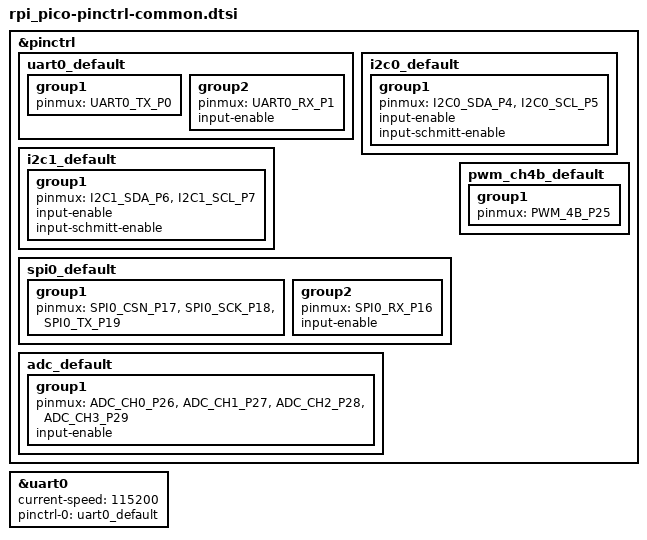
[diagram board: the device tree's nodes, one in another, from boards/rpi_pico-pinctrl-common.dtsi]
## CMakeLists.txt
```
# Minimum Cmake version required to build this project
cmake_minimum_required(VERSION 3.20)

# Locate the Zephyr RTOS source
find_package(Zephyr REQUIRED HINTS $ENV{ZEPHYR_BASE})

# Name the project
project(MeshFlipper)

list(APPEND CMAKE_MODULE_PATH ${ZEPHYR_BASE}/modules/nanopb)
include(nanopb)

# Make protobufs/ available as an import root so "meshtastic/foo.proto" resolves.
list(APPEND NANOPB_IMPORT_DIRS ${CMAKE_CURRENT_SOURCE_DIR}/protobufs)

# Compile mesh.proto and all its transitive dependencies.
zephyr_nanopb_sources(app
    protobufs/meshtastic/mesh.proto
    protobufs/meshtastic/channel.proto
    protobufs/meshtastic/config.proto
    protobufs/meshtastic/device_ui.proto
    protobufs/meshtastic/module_config.proto
    protobufs/meshtastic/atak.proto
    protobufs/meshtastic/portnums.proto
    protobufs/meshtastic/telemetry.proto
    protobufs/meshtastic/xmodem.proto
)

# Generated .pb.h files land in build/protobufs/meshtastic/ but are included as
# "meshtastic/X.pb.h", so build/protobufs/ must be on the include path.
target_include_directories(app PUBLIC ${CMAKE_CURRENT_BINARY_DIR}/protobufs)

# Locate the source code for the application
target_sources(
    app
    PRIVATE
    src/main.c
    src/models/ring_buffer.c
    src/models/mesh_message.c
    src/models/mesh_node.c
    src/hardware/uart_hal.c
    src/comms/uart_comms.c
    src/comms/protobuf_handler.c
    src/tasks/message_processor.c
    src/hardware/button_hal.c
    src/hardware/button.c
    src/ui/ui_button_handler.c
    src/hardware/display_hal.c
    src/hardware/display_hal_weact.c
    src/middleware/display_driver.c
    src/ui/on_screen_keyb.c
    src/ui/display_ui_core.c
    src/ui/display_ui_actions.c
    src/ui/display_ui_keyboard.c
)

target_include_directories(
    app
    PRIVATE
    include
)
```

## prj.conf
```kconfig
CONFIG_SERIAL=y
CONFIG_UART_INTERRUPT_DRIVEN=y
CONFIG_NANOPB=y
CONFIG_SPI=y
CONFIG_GPIO=y
```

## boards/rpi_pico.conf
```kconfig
# Was being used for usb serial console, but using cp2102 usb to uart bridge instead, so disabling usb device stack for now
# CONFIG_USB_DEVICE_STACK=y
# CONFIG_USB_DEVICE_VID=0x2FE3
# CONFIG_USB_DEVICE_PID=0x0004
# CONFIG_USB_DEVICE_PRODUCT="USB CDC-ACM serial console"

CONFIG_SERIAL=y
CONFIG_UART_INTERRUPT_DRIVEN=y
CONFIG_SPI=y
CONFIG_NANOPB=y
CONFIG_HEAP_MEM_POOL_SIZE=4096
CONFIG_MAIN_STACK_SIZE=4096
```

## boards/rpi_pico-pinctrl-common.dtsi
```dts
/*
 * Copyright (c) 2021, Yonatan Schachter
 * SPDX-License-Identifier: Apache-2.0
 */


#include <../../include/zephyr/dt-bindings/pinctrl/rpi-pico-pinctrl-common.h>

/* The Pico and Pico 2 are pin compatible. */
&pinctrl {
	uart0_default: uart0_default {
		group1 {
			pinmux = <UART0_TX_P0>;
		};

		group2 {
			pinmux = <UART0_RX_P1>;
			input-enable;
		};
	};

	i2c0_default: i2c0_default {
		group1 {
			pinmux = <I2C0_SDA_P4>, <I2C0_SCL_P5>;
			input-enable;
			input-schmitt-enable;
		};
	};

	i2c1_default: i2c1_default {
		group1 {
			pinmux = <I2C1_SDA_P6>, <I2C1_SCL_P7>;
			input-enable;
			input-schmitt-enable;
		};
	};

	spi0_default: spi0_default {
		group1 {
			pinmux = <SPI0_CSN_P17>, <SPI0_SCK_P18>, <SPI0_TX_P19>;
		};

		group2 {
			pinmux = <SPI0_RX_P16>;
			input-enable;
		};
	};

	pwm_ch4b_default: pwm_ch4b_default {
		group1 {
			pinmux = <PWM_4B_P25>;
		};
	};

	adc_default: adc_default {
		group1 {
			pinmux = <ADC_CH0_P26>, <ADC_CH1_P27>, <ADC_CH2_P28>, <ADC_CH3_P29>;
			input-enable;
		};
	};
};

/* Add this below your existing &pinctrl block */
&uart0 {
    status = "okay";
    current-speed = <115200>;
    pinctrl-0 = <&uart0_default>;
    pinctrl-names = "default";
};
```

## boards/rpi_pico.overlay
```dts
/ {
	leds {
		compatible = "gpio-leds";
		led0: led_0 {
			gpios = <&gpio0 6 GPIO_ACTIVE_HIGH>;
				label = "LED 0";
		};
	};

	aliases {
		led0 = &led0;
	};
};

&pinctrl {
	uart0_default: uart0_default {
		group1 {
			pinmux = <UART0_TX_P0>;
		};

		group2 {
			pinmux = <UART0_RX_P1>;
			input-enable;
		};
	};

	spi0_default: spi0_default {
		group1 {
			pinmux = <SPI0_SCK_P18 SPI0_TX_P19>;
		};
	};
};

&uart0 {
    status = "okay";
    current-speed = <115200>;
    pinctrl-0 = <&uart0_default>;
    pinctrl-names = "default";
};

&spi0 {
	status = "okay";
	pinctrl-0 = <&spi0_default>;
	pinctrl-names = "default";
};
```

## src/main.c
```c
#include <stdio.h>
#include <zephyr/kernel.h>
#include <zephyr/drivers/uart.h>

#include "hardware/uart_hal.h"
#include "hardware/display_hal_weact.h"
#include "ui/on_screen_keyb.h"
#include "comms/uart_comms.h"
#include "models/ring_buffer.h"
#include "models/mesh_message.h"
#include "models/mesh_node.h"
#include "tasks/message_processor.h"
#include "comms/protobuf_handler.h"
#include "ui/display_ui.h"
#include "ui/ui_button_handler.h"



// Global instances
struct messageHistory g_message_history = { .count = 0 };
struct nodeHistory g_node_list = { .count = 0 };
ring_buffer_t g_msg_ring_buffer;

// Display and UI instances
static display_ui_t g_display_ui;
static ui_button_context_t g_button_ctx;
static on_screen_keyb_t g_on_screen_keyb;




static int setup_uart_hal(void) 
{
    const struct device *uart_dev = DEVICE_DT_GET(DT_NODELABEL(uart0));

    if (uart_hal_init(&g_uart_hal, uart_dev) != 0) {
        printk("UART HAL init failed\n");
        return -1;
    }

    if (uart_hal_configure_default(&g_uart_hal) != 0) {
        printk("UART configure failed\n");
        return -1;
    }

    uart_comms_init(&g_uart_comms, &g_uart_hal);

    // Set UART callback to HAL's ISR handler
    uart_irq_callback_user_data_set(uart_dev, uart_hal_isr_handler, &g_uart_hal);

    // Set the HAL callback to forward to uart_comms
    uart_hal_set_rx_callback(&g_uart_hal, uart_comms_process_byte, &g_uart_comms);
    
    uart_hal_irq_enable(&g_uart_hal);
    
    return 0;
}

static int setup_message_processor(void) 
{
    if (message_processor_init(&g_msg_ring_buffer, 
                               &g_message_history, 
                               &g_node_list) != 0) {
        printk("Message processor init failed\n");
        return -1;
    } 

    if (message_processor_start() != 0) {
        printk("Message processor start failed\n");
        return -1;
    }

    return 0;
}

static int setup_display(void)
{
    display_hal_config_t hal_config = weact_display_get_config();
    
    int ret = display_ui_init(&g_display_ui, &hal_config, &g_message_history, &g_node_list);
    if (ret < 0) {
        printk("Display UI init failed: %d\n", ret);
        return -1;
    }
    message_processor_set_display_ui(&g_display_ui);
    display_ui_show_boot(&g_display_ui);

    return 0;
}

static int setup_buttons(void)
{
    int ret = ui_button_handler_init(&g_button_ctx, &g_display_ui);
    if (ret < 0) {
        printk("Button handler init failed: %d\n", ret);
        return -1;
    }

    // Start button handler thread
    ret = ui_button_handler_start();
    if (ret < 0) {
        printk("Button handler start failed: %d\n", ret);
        return -1;
    }

    return 0;
}

static int setup_on_screen_keyb(void) {
    int ret = init_on_screen_keyb(&g_on_screen_keyb);
    if (ret < 0) {
        printk("On-screen keyb init failed");
    }

    return 0;
}

static int setup(void) 
{
    ring_buffer_init(&g_msg_ring_buffer);

    if (setup_uart_hal() != 0) {
        printk("UART setup failed\n");
        return -1;
    }

    if (setup_message_processor() != 0) {
        printk("Message processor setup failed\n");
        return -1;
    }

    if (setup_display() != 0) {
        printk("Display setup failed - continuing without display\n");
        return -1;
    }

    if (setup_buttons() != 0) {
        printk("Button setup failed - continuing without buttons\n");
        return -1;
    }

    if (setup_on_screen_keyb() != 0) {
        printk("On-screen keyb setup failed - continuing without on-screen keyb\n");
        return -1;
    }

    return 0;
}



// Main loop helper checks for outgoing messages from the UI, and sends them when they appear.
static void check_for_outgoing_messages(void)
{
    struct screen_ui_outgoing outgoing;
    if (display_ui_take_outgoing(&g_display_ui, &outgoing))
    {
        int send_ret = send_text_message((uint32_t)outgoing.target_node,
                                         outgoing.text,
                                         strlen(outgoing.text));
        if (send_ret < 0)
        {
            printk("Send failed: %d\n", send_ret);
        }
    }
}

/*
    Main loop helper checks for new messages and updates the display.
    Checks that the latest message in the message history is new by comparing its ID to the last handled incoming message ID stored in the display UI state.
    If a new message is detected and we're not in a thread or compose screen, refresh the inbox display and update the last handled incoming message ID.
*/
static void check_new_messages(void)
{
    if (g_display_ui.initialized && g_message_history.count > 0)
    {
        int last_idx = g_message_history.count - 1;
        if (g_message_history.messages[last_idx].id != g_display_ui.last_handled_incoming_id)
        {
            if (!g_display_ui.thread_active && !g_display_ui.compose_active)
            {
                display_ui_refresh(&g_display_ui);
                g_display_ui.last_handled_incoming_id = g_message_history.messages[last_idx].id;
            }
        }
    }
}

int main(void)
{
    int main_poll_interval_ms = 50;

    if (setup() != 0) {
        printk("Setup failed\n");
        return -1;
    }

    printk("\nMeshFlipper ready!\n");
    
    if (!message_processor_wait_for_my_node_info(WAIT_FOR_NODE_INFO_TIMEOUT_MS)) {
        printk("Failed to get my node info\n");
        return -1;
    } 

    if (!g_display_ui.initialized){
        printk("Display UI not initialized\n");
        return -1;
    }

    display_ui_show_inbox(&g_display_ui);

    // Main loop
    while (1) {
        check_for_outgoing_messages();
        check_new_messages();

        k_sleep(K_MSEC(main_poll_interval_ms));
    }
    
    return 0;
}
```

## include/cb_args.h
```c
#ifndef CB_ARGS_H
#define CB_ARGS_H

struct cb_args {
    struct messageHistory *message_history;
    struct nodeHistory *node_list;
};

#endif // CB_ARGS_H
```
